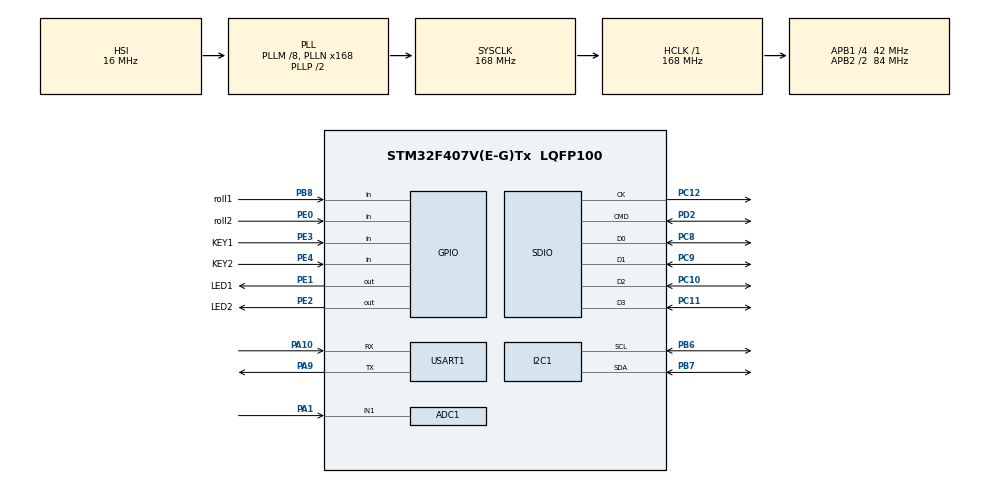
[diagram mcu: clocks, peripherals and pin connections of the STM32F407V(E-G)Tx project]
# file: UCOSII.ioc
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ADC1.Channel-0\#ChannelRegularConversion=ADC_CHANNEL_1
ADC1.NbrOfConversionFlag=1
ADC1.Rank-0\#ChannelRegularConversion=1
ADC1.SamplingTime-0\#ChannelRegularConversion=ADC_SAMPLETIME_480CYCLES
ADC1.master=1
Dma.ADC1.0.Direction=DMA_PERIPH_TO_MEMORY
Dma.ADC1.0.FIFOMode=DMA_FIFOMODE_DISABLE
Dma.ADC1.0.Instance=DMA2_Stream0
Dma.ADC1.0.MemDataAlignment=DMA_MDATAALIGN_HALFWORD
Dma.ADC1.0.MemInc=DMA_MINC_ENABLE
Dma.ADC1.0.Mode=DMA_NORMAL
Dma.ADC1.0.PeriphDataAlignment=DMA_PDATAALIGN_HALFWORD
Dma.ADC1.0.PeriphInc=DMA_PINC_DISABLE
Dma.ADC1.0.Priority=DMA_PRIORITY_LOW
Dma.Request0=ADC1
FATFS._CODE_PAGE=936
FATFS._USE_LFN=2
FATFS._VOLUMES=2
I2C1.I2C_Mode=I2C_Fast
Mcu.Family=STM32F4
Mcu.Name=STM32F407V(E-G)Tx
Mcu.Package=LQFP100
NVIC.DMA2_Stream0_IRQn=true\:0\:0\:false\:false\:true\:false\:true
NVIC.PriorityGroup=NVIC_PRIORITYGROUP_4
NVIC.SDIO_IRQn=true\:0\:0\:false\:false\:true\:true\:true
NVIC.USART1_IRQn=true\:0\:0\:false\:false\:true\:true\:true
PA1.Signal=ADCx_IN1
PA10.Mode=Asynchronous
PA10.Signal=USART1_RX
PA9.Mode=Asynchronous
PA9.Signal=USART1_TX
PB6.Mode=I2C
PB6.Signal=I2C1_SCL
PB7.Mode=I2C
PB7.Signal=I2C1_SDA
PB8.GPIO_Label=roll1
PB8.GPIO_PuPd=GPIO_PULLUP
PB8.Signal=GPIO_Input
PC10.Mode=SD_4_bits_Wide_bus
PC10.Signal=SDIO_D2
PC11.Mode=SD_4_bits_Wide_bus
PC11.Signal=SDIO_D3
PC12.Mode=SD_4_bits_Wide_bus
PC12.Signal=SDIO_CK
PC14-OSC32_IN.Mode=LSE-External-Oscillator
PC14-OSC32_IN.Signal=RCC_OSC32_IN
PC15-OSC32_OUT.Mode=LSE-External-Oscillator
PC15-OSC32_OUT.Signal=RCC_OSC32_OUT
PC8.Mode=SD_4_bits_Wide_bus
PC8.Signal=SDIO_D0
PC9.Mode=SD_4_bits_Wide_bus
PC9.Signal=SDIO_D1
PD2.Mode=SD_4_bits_Wide_bus
PD2.Signal=SDIO_CMD
PE0.GPIO_Label=roll2
PE0.GPIO_PuPd=GPIO_PULLUP
PE0.Signal=GPIO_Input
PE1.GPIO_Label=LED1
PE1.GPIO_PuPd=GPIO_PULLDOWN
PE1.Signal=GPIO_Output
PE2.GPIO_Label=LED2
PE2.GPIO_PuPd=GPIO_PULLDOWN
PE2.Signal=GPIO_Output
PE3.GPIO_Label=KEY1
PE3.GPIO_PuPd=GPIO_PULLUP
PE3.Signal=GPIO_Input
PE4.GPIO_Label=KEY2
PE4.GPIO_PuPd=GPIO_PULLUP
PE4.Signal=GPIO_Input
PH0-OSC_IN.Mode=HSE-External-Oscillator
PH0-OSC_IN.Signal=RCC_OSC_IN
PH1-OSC_OUT.Mode=HSE-External-Oscillator
PH1-OSC_OUT.Signal=RCC_OSC_OUT
ProjectManager.HeapSize=0x200
ProjectManager.StackSize=0x1000
ProjectManager.TargetToolchain=MDK-ARM V5.27
RCC.48MHZClocksFreq_Value=48000000
RCC.AHBFreq_Value=168000000
RCC.APB1CLKDivider=RCC_HCLK_DIV4
RCC.APB1Freq_Value=42000000
RCC.APB1TimFreq_Value=84000000
RCC.APB2CLKDivider=RCC_HCLK_DIV2
RCC.APB2Freq_Value=84000000
RCC.APB2TimFreq_Value=168000000
RCC.CortexFreq_Value=168000000
RCC.HCLKFreq_Value=168000000
RCC.HSE_VALUE=25000000
RCC.HSI_VALUE=16000000
RCC.PLLM=8
RCC.PLLN=168
RCC.PLLQ=7
RCC.SYSCLKFreq_VALUE=168000000
RCC.SYSCLKSource=RCC_SYSCLKSOURCE_PLLCLK
RCC.VCOOutputFreq_Value=336000000
SDIO.ClockDiv=4
SH.ADCx_IN1.0=ADC1_IN1,IN1
USART1.VirtualMode=VM_ASYNC
VP_FATFS_VS_SDIO.Mode=SDIO
board=custom

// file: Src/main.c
/* USER CODE BEGIN Header */
/**
  ******************************************************************************
  * @file           : main.c
  * @brief          : Main program body
  ******************************************************************************
  * @attention
  *
  * <h2><center>&copy; Copyright (c) 2020 STMicroelectronics.
  * All rights reserved.</center></h2>
  *
  * This software component is licensed by ST under BSD 3-Clause license,
  * the "License"; You may not use this file except in compliance with the
  * License. You may obtain a copy of the License at:
  *                        opensource.org/licenses/BSD-3-Clause
  *
  ******************************************************************************
  */
/* USER CODE END Header */

#include "main.h"
#include "adc.h"
#include "dma.h"
#include "fatfs.h"
#include "i2c.h"
#include "sdio.h"
#include "usart.h"
#include "gpio.h"

/* USER CODE BEGIN Includes */
#include "ucos_main.h"
#include "oled.h"
/* USER CODE END Includes */

void SystemClock_Config(void);

int main(void)
{

  /* MCU Configuration--------------------------------------------------------*/

  /* Reset of all peripherals, Initializes the Flash interface and the Systick. */
  HAL_Init();

  /* Configure the system clock */
  SystemClock_Config();

  /* Initialize all configured peripherals */
  MX_GPIO_Init();
  MX_DMA_Init();
  MX_I2C1_Init();
  MX_SDIO_SD_Init();
  MX_FATFS_Init();
  MX_ADC1_Init();
  MX_USART1_UART_Init();
  /* USER CODE BEGIN 2 */

	ucos_main();
  /* USER CODE END 2 */

  /* Infinite loop */
  while (1)
  {

  }
}

void SystemClock_Config(void)
{
  RCC_OscInitTypeDef RCC_OscInitStruct = {0};
  RCC_ClkInitTypeDef RCC_ClkInitStruct = {0};

  /** Configure the main internal regulator output voltage
  */
  __HAL_RCC_PWR_CLK_ENABLE();
  __HAL_PWR_VOLTAGESCALING_CONFIG(PWR_REGULATOR_VOLTAGE_SCALE1);
  /** Initializes the CPU, AHB and APB busses clocks
  */
  RCC_OscInitStruct.OscillatorType = RCC_OSCILLATORTYPE_HSI;
  RCC_OscInitStruct.HSIState = RCC_HSI_ON;
  RCC_OscInitStruct.HSICalibrationValue = RCC_HSICALIBRATION_DEFAULT;
  RCC_OscInitStruct.PLL.PLLState = RCC_PLL_ON;
  RCC_OscInitStruct.PLL.PLLSource = RCC_PLLSOURCE_HSI;
  RCC_OscInitStruct.PLL.PLLM = 8;
  RCC_OscInitStruct.PLL.PLLN = 168;
  RCC_OscInitStruct.PLL.PLLP = RCC_PLLP_DIV2;
  RCC_OscInitStruct.PLL.PLLQ = 7;
  if (HAL_RCC_OscConfig(&RCC_OscInitStruct) != HAL_OK)
  {
    Error_Handler();
  }
  /** Initializes the CPU, AHB and APB busses clocks
  */
  RCC_ClkInitStruct.ClockType = RCC_CLOCKTYPE_HCLK|RCC_CLOCKTYPE_SYSCLK
                              |RCC_CLOCKTYPE_PCLK1|RCC_CLOCKTYPE_PCLK2;
  RCC_ClkInitStruct.SYSCLKSource = RCC_SYSCLKSOURCE_PLLCLK;
  RCC_ClkInitStruct.AHBCLKDivider = RCC_SYSCLK_DIV1;
  RCC_ClkInitStruct.APB1CLKDivider = RCC_HCLK_DIV4;
  RCC_ClkInitStruct.APB2CLKDivider = RCC_HCLK_DIV2;

  if (HAL_RCC_ClockConfig(&RCC_ClkInitStruct, FLASH_LATENCY_5) != HAL_OK)
  {
    Error_Handler();
  }
}

void Error_Handler(void)
{
}

/************************ (C) COPYRIGHT STMicroelectronics *****END OF FILE****/
